# PIC32MX170F256B register map
Registers are 32-bit, access not given, reset 0x0 unless marked. A register's access mark holds for its fields unless they carry their own. Offsets are from the block's base; [hi:lo] are bit positions; {n}, {i} and the like mark numbered series; 'fields as' and 'values as' point back to an identical list.

## CVR — CVR peripheral
Base 0xBF809800
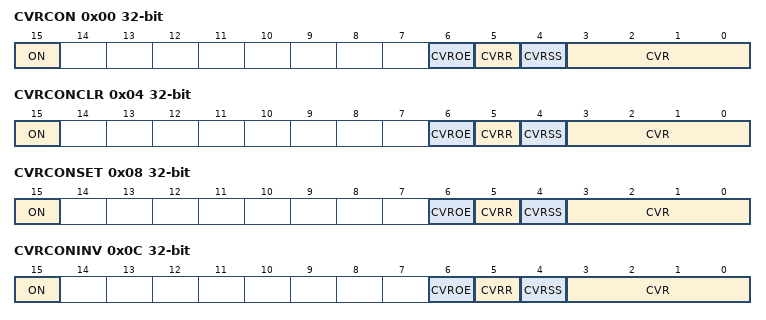
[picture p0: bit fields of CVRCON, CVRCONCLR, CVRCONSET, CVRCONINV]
0x00 CVRCON
  [15] ON, [6] CVROE, [5] CVRR, [4] CVRSS, [3:0] CVR
0x04 CVRCONCLR
  [15] ON, [6] CVROE, [5] CVRR, [4] CVRSS, [3:0] CVR
0x08 CVRCONSET
  [15] ON, [6] CVROE, [5] CVRR, [4] CVRSS, [3:0] CVR
0x0C CVRCONINV
  [15] ON, [6] CVROE, [5] CVRR, [4] CVRSS, [3:0] CVR

## CMP1 — CMP1 peripheral
Base 0xBF80A000
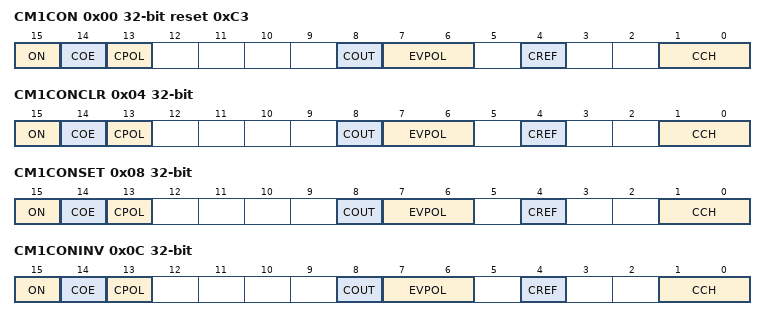
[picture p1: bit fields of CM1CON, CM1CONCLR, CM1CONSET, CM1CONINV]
0x00 CM1CON reset 0xC3
  [15] ON, [14] COE, [13] CPOL, [8] COUT, [7:6] EVPOL, [4] CREF, [1:0] CCH
0x04 CM1CONCLR
  fields as CM1CON
0x08 CM1CONSET
  fields as CM1CON
0x0C CM1CONINV
  fields as CM1CON

## CMP2 — CMP2 peripheral
Base 0xBF80A010
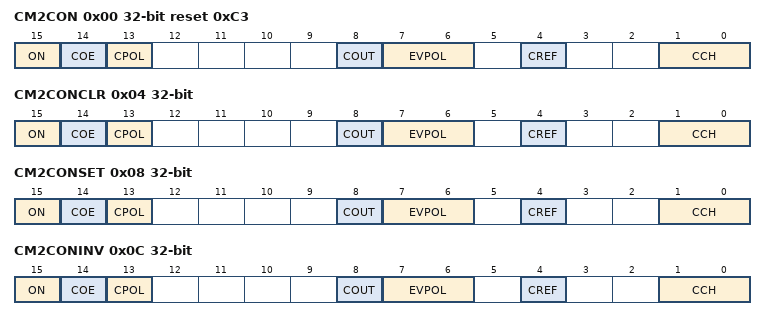
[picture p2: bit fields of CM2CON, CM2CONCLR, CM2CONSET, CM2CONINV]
0x00 CM2CON reset 0xC3
  [15] ON, [14] COE, [13] CPOL, [8] COUT, [7:6] EVPOL, [4] CREF, [1:0] CCH
0x04 CM2CONCLR
  fields as CM2CON
0x08 CM2CONSET
  fields as CM2CON
0x0C CM2CONINV
  fields as CM2CON

## CMP3 — CMP3 peripheral
Base 0xBF80A020
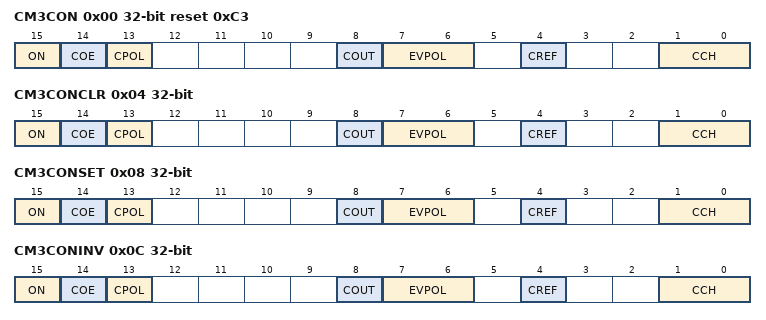
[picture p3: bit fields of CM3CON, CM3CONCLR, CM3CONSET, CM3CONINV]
0x00 CM3CON reset 0xC3
  [15] ON, [14] COE, [13] CPOL, [8] COUT, [7:6] EVPOL, [4] CREF, [1:0] CCH
0x04 CM3CONCLR
  fields as CM3CON
0x08 CM3CONSET
  fields as CM3CON
0x0C CM3CONINV
  fields as CM3CON

## CMP — CMP peripheral
Base 0xBF80A060
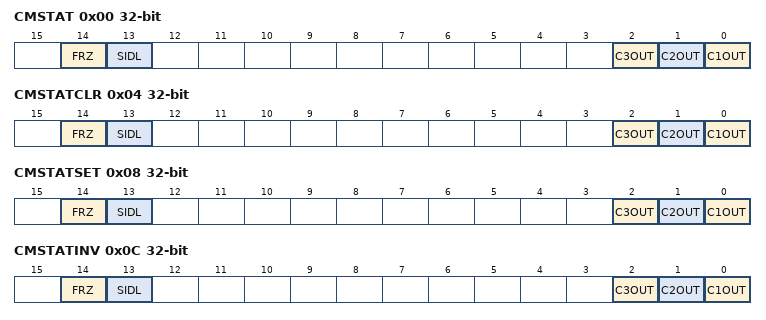
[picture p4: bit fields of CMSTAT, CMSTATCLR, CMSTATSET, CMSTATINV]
0x00 CMSTAT
  [14] FRZ, [13] SIDL, [2] C3OUT, [1] C2OUT, [0] C1OUT
0x04 CMSTATCLR
  [14] FRZ, [13] SIDL, [2] C3OUT, [1] C2OUT, [0] C1OUT
0x08 CMSTATSET
  [14] FRZ, [13] SIDL, [2] C3OUT, [1] C2OUT, [0] C1OUT
0x0C CMSTATINV
  [14] FRZ, [13] SIDL, [2] C3OUT, [1] C2OUT, [0] C1OUT

## CTMU — CTMU peripheral
Base 0xBF80A200
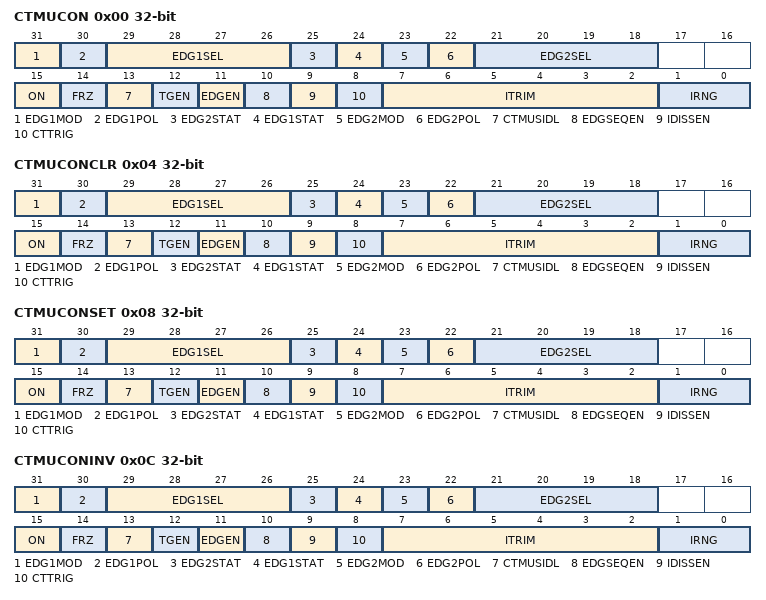
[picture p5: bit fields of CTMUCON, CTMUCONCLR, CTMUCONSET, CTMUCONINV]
0x00 CTMUCON
  [31] EDG1MOD, [30] EDG1POL, [29:26] EDG1SEL, [25] EDG2STAT, [24] EDG1STAT, [23] EDG2MOD, [22] EDG2POL, [21:18] EDG2SEL, [15] ON, [14] FRZ, [13] CTMUSIDL, [12] TGEN, [11] EDGEN, [10] EDGSEQEN, [9] IDISSEN, [8] CTTRIG, [7:2] ITRIM, [1:0] IRNG
0x04 CTMUCONCLR
  fields as CTMUCON
0x08 CTMUCONSET
  fields as CTMUCON
0x0C CTMUCONINV
  fields as CTMUCON

## OSC — OSC peripheral
Base 0xBF80F000
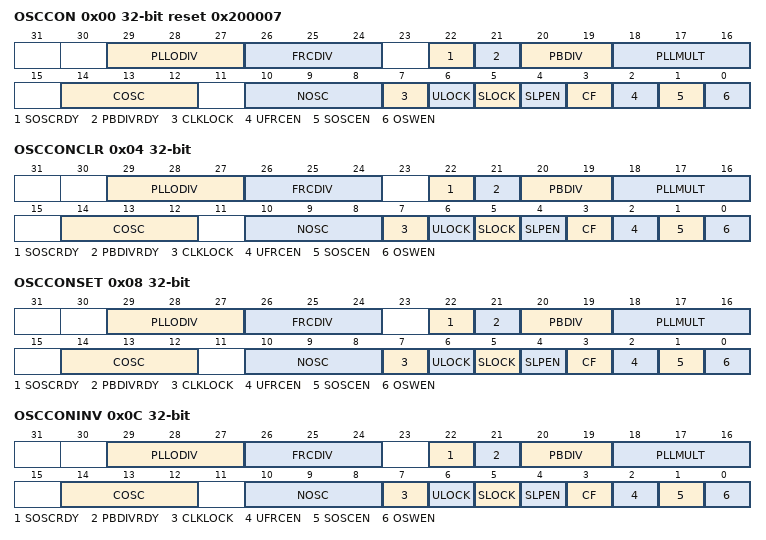
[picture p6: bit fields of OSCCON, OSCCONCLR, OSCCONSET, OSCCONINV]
0x00 OSCCON reset 0x200007
  [29:27] PLLODIV, [26:24] FRCDIV, [22] SOSCRDY, [21] PBDIVRDY, [20:19] PBDIV, [18:16] PLLMULT, [14:12] COSC, [10:8] NOSC, [7] CLKLOCK, [6] ULOCK, [5] SLOCK, [4] SLPEN, [3] CF, [2] UFRCEN, [1] SOSCEN, [0] OSWEN
0x04 OSCCONCLR
  fields as OSCCON
0x08 OSCCONSET
  fields as OSCCON
0x0C OSCCONINV
  fields as OSCCON
0x10 OSCTUN
  [5:0] TUN
0x14 OSCTUNCLR
  [5:0] TUN
0x18 OSCTUNSET
  [5:0] TUN
0x1C OSCTUNINV
  [5:0] TUN
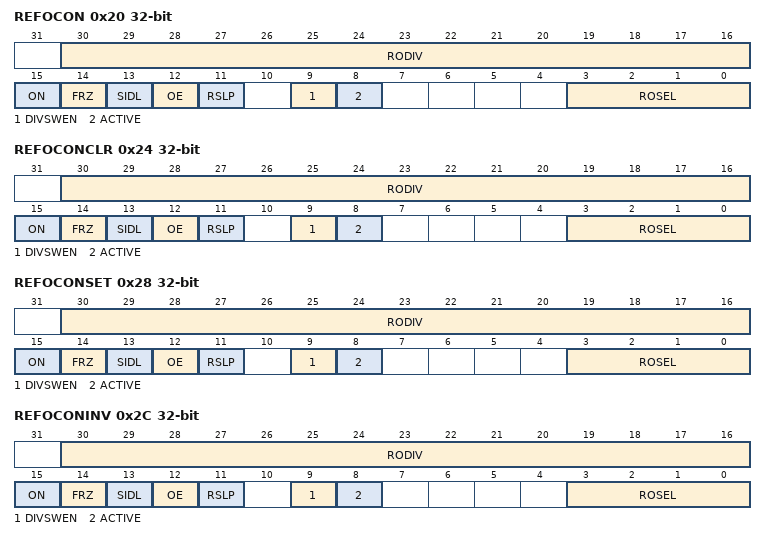
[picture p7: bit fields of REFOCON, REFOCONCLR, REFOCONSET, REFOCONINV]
0x20 REFOCON
  [30:16] RODIV, [15] ON, [14] FRZ, [13] SIDL, [12] OE, [11] RSLP, [9] DIVSWEN, [8] ACTIVE, [3:0] ROSEL
0x24 REFOCONCLR
  fields as REFOCON
0x28 REFOCONSET
  fields as REFOCON
0x2C REFOCONINV
  fields as REFOCON
0x30 REFOTRIM
  [31:23] ROTRIM
0x34 REFOTRIMCLR
  [31:23] ROTRIM
0x38 REFOTRIMSET
  [31:23] ROTRIM
0x3C REFOTRIMINV
  [31:23] ROTRIM

## CFG — CFG peripheral
Base 0xBF80F200
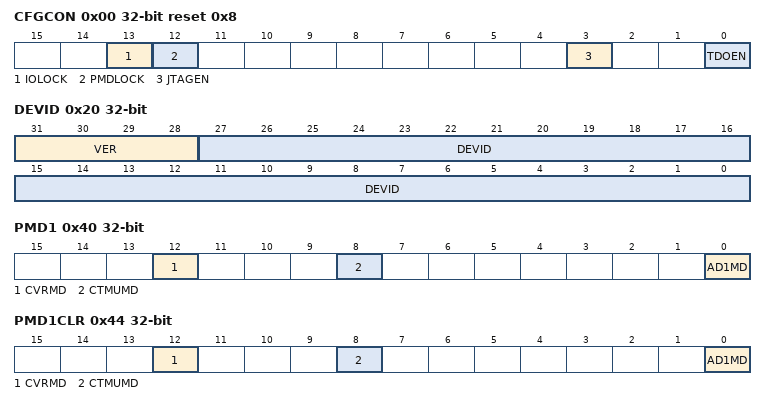
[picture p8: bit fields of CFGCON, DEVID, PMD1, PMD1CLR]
0x00 CFGCON reset 0x8
  [13] IOLOCK, [12] PMDLOCK, [3] JTAGEN, [0] TDOEN
0x20 DEVID
  [31:28] VER, [27:0] DEVID
0x30 SYSKEY
0x34 SYSKEYCLR
  [31:0] SYSKEY
0x38 SYSKEYSET
  [31:0] SYSKEY
0x3C SYSKEYINV
  [31:0] SYSKEY
0x40 PMD1
  [12] CVRMD, [8] CTMUMD, [0] AD1MD
0x44 PMD1CLR
  [12] CVRMD, [8] CTMUMD, [0] AD1MD
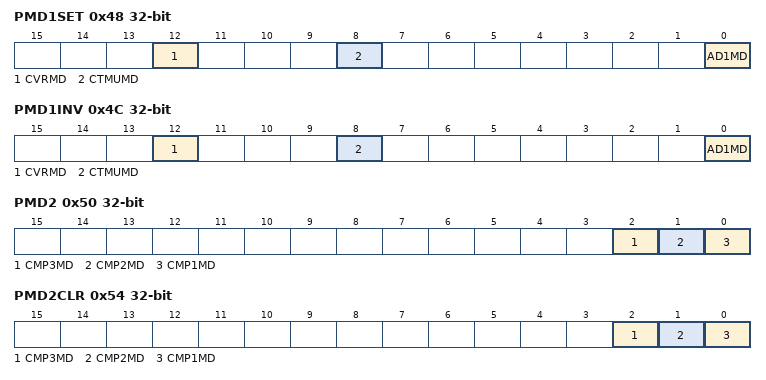
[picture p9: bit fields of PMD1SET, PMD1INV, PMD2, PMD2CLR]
0x48 PMD1SET
  [12] CVRMD, [8] CTMUMD, [0] AD1MD
0x4C PMD1INV
  [12] CVRMD, [8] CTMUMD, [0] AD1MD
0x50 PMD2
  [2] CMP3MD, [1] CMP2MD, [0] CMP1MD
0x54 PMD2CLR
  [2] CMP3MD, [1] CMP2MD, [0] CMP1MD
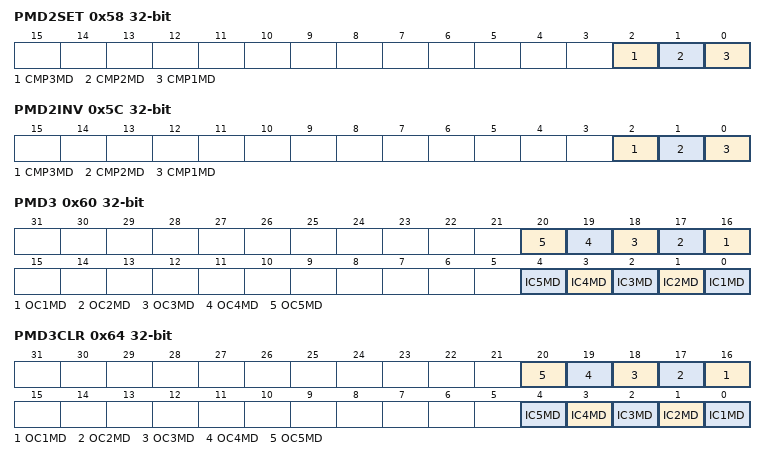
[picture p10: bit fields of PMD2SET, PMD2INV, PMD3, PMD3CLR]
0x58 PMD2SET
  [2] CMP3MD, [1] CMP2MD, [0] CMP1MD
0x5C PMD2INV
  [2] CMP3MD, [1] CMP2MD, [0] CMP1MD
0x60 PMD3
  [n+15] OC{n}MD (n=1..5), [n-1] IC{n}MD (n=1..5)
0x64 PMD3CLR
  [n+15] OC{n}MD (n=1..5), [n-1] IC{n}MD (n=1..5)
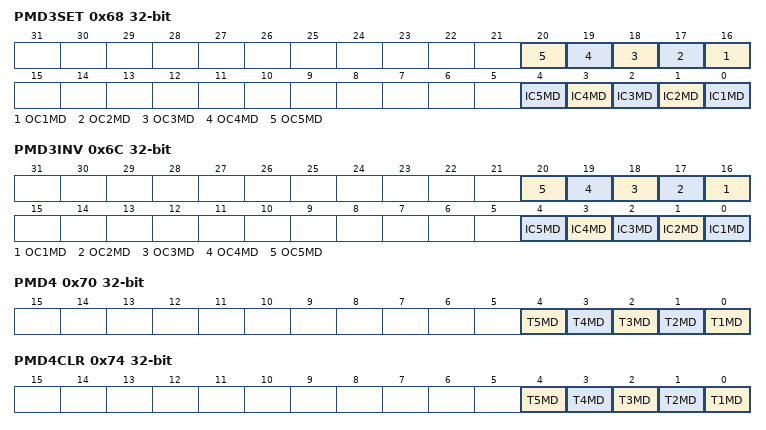
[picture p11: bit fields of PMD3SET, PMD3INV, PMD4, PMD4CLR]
0x68 PMD3SET
  [n+15] OC{n}MD (n=1..5), [n-1] IC{n}MD (n=1..5)
0x6C PMD3INV
  [n+15] OC{n}MD (n=1..5), [n-1] IC{n}MD (n=1..5)
0x70 PMD4
  [n-1] T{n}MD (n=1..5)
0x74 PMD4CLR
  [n-1] T{n}MD (n=1..5)
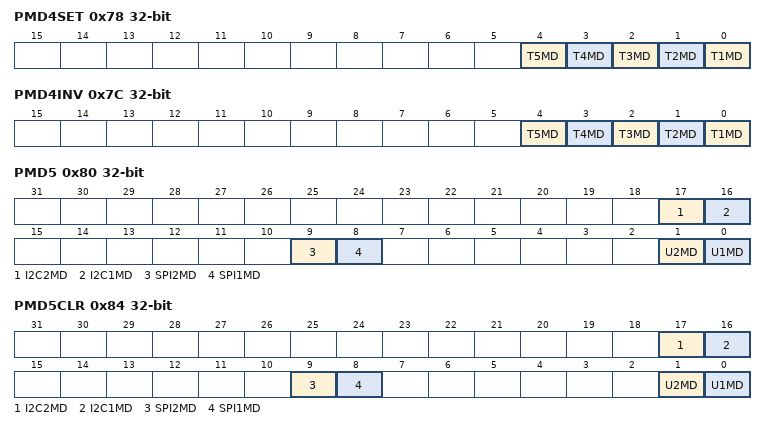
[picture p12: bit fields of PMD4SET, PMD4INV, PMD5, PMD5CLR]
0x78 PMD4SET
  [n-1] T{n}MD (n=1..5)
0x7C PMD4INV
  [n-1] T{n}MD (n=1..5)
0x80 PMD5
  [17] I2C2MD, [16] I2C1MD, [9] SPI2MD, [8] SPI1MD, [1] U2MD, [0] U1MD
0x84 PMD5CLR
  [17] I2C2MD, [16] I2C1MD, [9] SPI2MD, [8] SPI1MD, [1] U2MD, [0] U1MD
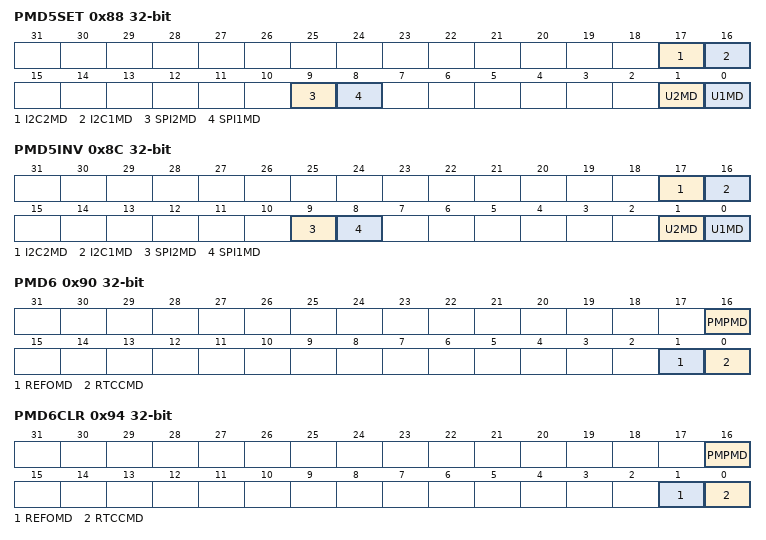
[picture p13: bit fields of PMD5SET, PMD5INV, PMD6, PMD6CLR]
0x88 PMD5SET
  [17] I2C2MD, [16] I2C1MD, [9] SPI2MD, [8] SPI1MD, [1] U2MD, [0] U1MD
0x8C PMD5INV
  [17] I2C2MD, [16] I2C1MD, [9] SPI2MD, [8] SPI1MD, [1] U2MD, [0] U1MD
0x90 PMD6
  [16] PMPMD, [1] REFOMD, [0] RTCCMD
0x94 PMD6CLR
  [16] PMPMD, [1] REFOMD, [0] RTCCMD
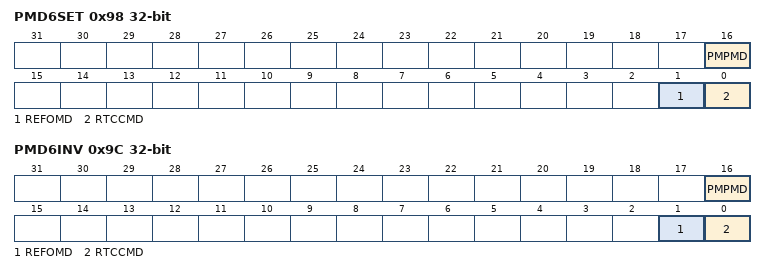
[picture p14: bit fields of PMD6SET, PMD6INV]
0x98 PMD6SET
  [16] PMPMD, [1] REFOMD, [0] RTCCMD
0x9C PMD6INV
  [16] PMPMD, [1] REFOMD, [0] RTCCMD
